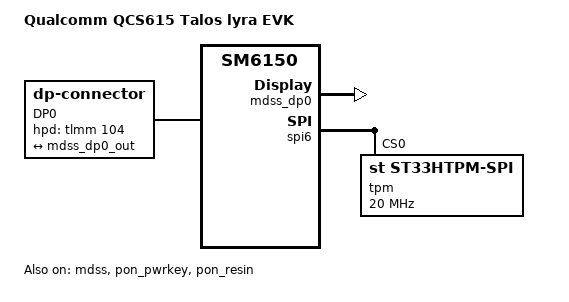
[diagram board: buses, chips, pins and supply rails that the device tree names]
// SPDX-License-Identifier: BSD-3-Clause
/*
 * Copyright (c) Qualcomm Technologies, Inc. and/or its subsidiaries.
 */
/dts-v1/;

#include "talos-lyra-evk-som.dtsi"

/ {
	model = "Qualcomm QCS615 Talos lyra EVK";
	compatible = "qcom,talos-lyra-evk", "qcom,talos-lyra-evk-som", "qcom,qcs615",
		     "qcom,sm6150";
	chassis-type = "embedded";

	dp0-connector {
		compatible = "dp-connector";
		label = "DP0";
		type = "full-size";

		hpd-gpios = <&tlmm 104 GPIO_ACTIVE_HIGH>;

		port {
			dp0_connector_in: endpoint {
				remote-endpoint = <&mdss_dp0_out>;
			};
		};
	};
};

&mdss {
        status = "okay";
};

&mdss_dp0 {
        status = "okay";
};

&mdss_dp0_out {
        link-frequencies = /bits/ 64 <1620000000 2700000000 5400000000>;
        remote-endpoint = <&dp0_connector_in>;
};

&pon_pwrkey {
	status = "okay";
};

&pon_resin {
	linux,code = <KEY_VOLUMEDOWN>;

	status = "okay";
};

&spi6 {
        status = "okay";

        tpm@0 {
                compatible = "st,st33htpm-spi", "tcg,tpm_tis-spi";
                reg = <0>;
                spi-max-frequency = <20000000>;
        };
};
